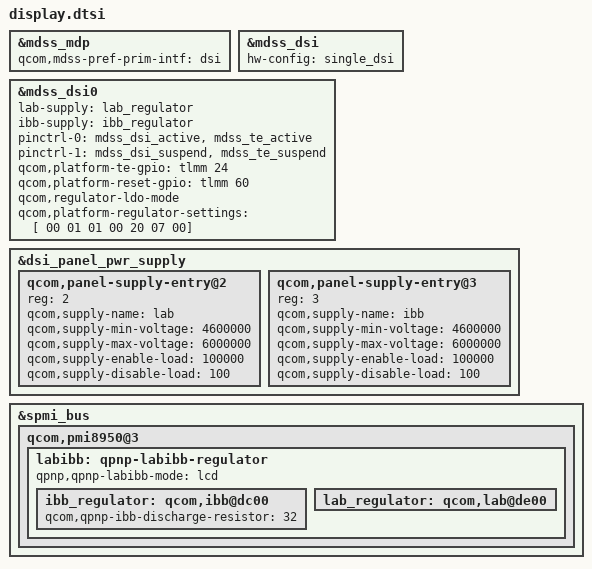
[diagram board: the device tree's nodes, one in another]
/* FROM: S88536AA2.dtsi */
&mdss_mdp {
	qcom,mdss-pref-prim-intf = "dsi";
};

&mdss_dsi {
	hw-config = "single_dsi";
};

&mdss_dsi0 {
	lab-supply = <&lab_regulator>;
	ibb-supply = <&ibb_regulator>;

	pinctrl-names = "mdss_default", "mdss_sleep";
	pinctrl-0 = <&mdss_dsi_active &mdss_te_active>;
	pinctrl-1 = <&mdss_dsi_suspend &mdss_te_suspend>;

	qcom,platform-te-gpio = <&tlmm 24 0>;
	qcom,platform-reset-gpio = <&tlmm 60 0>;

	qcom,regulator-ldo-mode;
	qcom,platform-regulator-settings = [ 00 01 01 00 20 07 00];

};

&labibb {
	status = "ok";
	qpnp,qpnp-labibb-mode = "lcd";
};

&ibb_regulator {
	qcom,qpnp-ibb-discharge-resistor = <32>;
};

&dsi_panel_pwr_supply {
	qcom,panel-supply-entry@2 {
		reg = <2>;
		qcom,supply-name = "lab";
		qcom,supply-min-voltage = <4600000>;
		qcom,supply-max-voltage = <6000000>;
		qcom,supply-enable-load = <100000>;
		qcom,supply-disable-load = <100>;
	};

	qcom,panel-supply-entry@3 {
		reg = <3>;
		qcom,supply-name = "ibb";
		qcom,supply-min-voltage = <4600000>;
		qcom,supply-max-voltage = <6000000>;
		qcom,supply-enable-load = <100000>;
		qcom,supply-disable-load = <100>;
	};
};

&spmi_bus {
	qcom,pmi8950@3 {
		labibb: qpnp-labibb-regulator {
			ibb_regulator: qcom,ibb@dc00 {
				/delete-property/
					qcom,qpnp-ibb-use-default-voltage;
			};

			lab_regulator: qcom,lab@de00 {
				/delete-property/
					qcom,qpnp-ibb-use-default-voltage;
			};
		};
	};
};
